VERSION ""

NS_ :

BS_:

BU_: XXX

BO_ 23 BRAKE_RELATED: 8 XXX
 SG_ BRAKE_ON : 0|1@0+ (1,0) [0|1] "" XXX
 SG_ NO_BRAKE : 15|1@0+ (1,0) [0|1] "" XXX

BO_ 24 HYBRID_RELATED: 8 XXX
 SG_ NEW_SIGNAL_1 : 7|13@0+ (1,0) [0|8191] "" XXX
 SG_ NEW_SIGNAL_2 : 38|9@0+ (1,0) [0|511] "" XXX

BO_ 80 ENGINE_START: 8 XXX
 SG_ ENGINE_ON : 1|1@0+ (1,0) [0|1] "" XXX

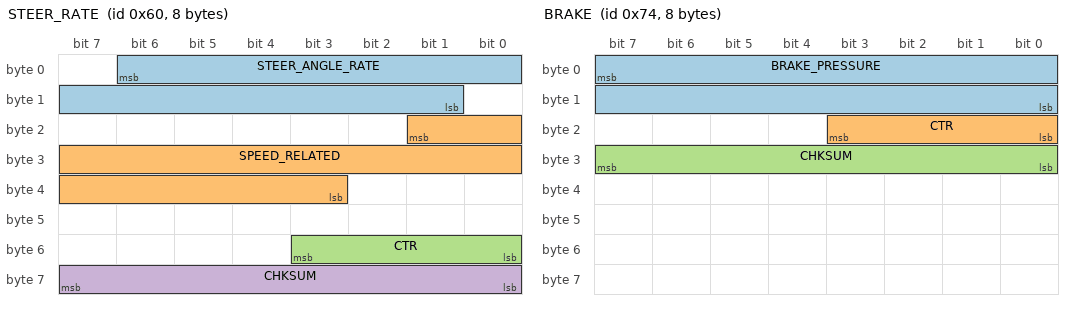
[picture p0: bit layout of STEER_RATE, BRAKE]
BO_ 96 STEER_RATE: 8 XXX
 SG_ STEER_ANGLE_RATE : 6|14@0+ (1,-8192) [0|16383] "" XXX
 SG_ SPEED_RELATED : 17|15@0+ (1,-10000) [0|32767] "" XXX
 SG_ CTR : 51|4@0+ (1,0) [0|15] "" XXX
 SG_ CHKSUM : 63|8@0+ (1,0) [0|255] "" XXX

BO_ 116 BRAKE: 8 XXX
 SG_ BRAKE_PRESSURE : 7|16@0+ (1,0) [0|65535] "" XXX
 SG_ CTR : 19|4@0+ (1,0) [0|15] "" XXX
 SG_ CHKSUM : 31|8@0+ (1,0) [0|255] "" XXX

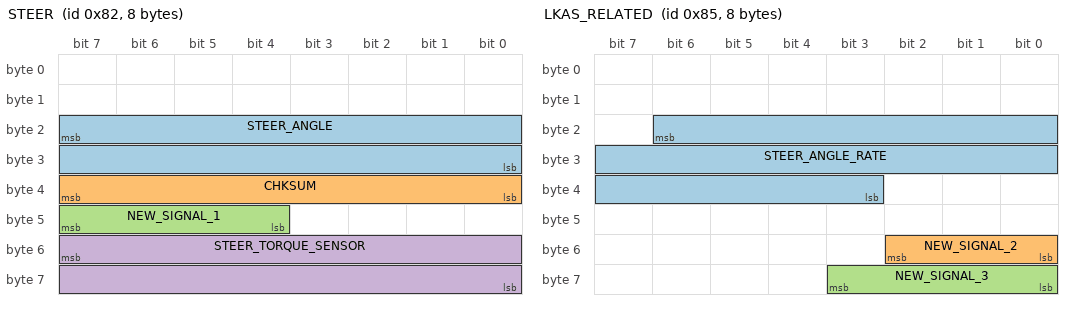
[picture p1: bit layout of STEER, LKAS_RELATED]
BO_ 130 STEER: 8 XXX
 SG_ STEER_ANGLE : 23|16@0+ (0.05,-1600) [500|-500] "deg" XXX
 SG_ CHKSUM : 39|8@0+ (1,0) [0|255] "" XXX
 SG_ NEW_SIGNAL_1 : 47|4@0+ (1,0) [0|15] "" XXX
 SG_ STEER_TORQUE_SENSOR : 55|16@0+ (1,0) [0|65535] "" XXX

BO_ 133 LKAS_RELATED: 8 XXX
 SG_ STEER_ANGLE_RATE : 22|20@0+ (1,0) [0|1048575] "" XXX
 SG_ NEW_SIGNAL_2 : 50|3@0+ (1,0) [0|7] "" XXX
 SG_ NEW_SIGNAL_3 : 59|4@0+ (1,0) [0|15] "" XXX

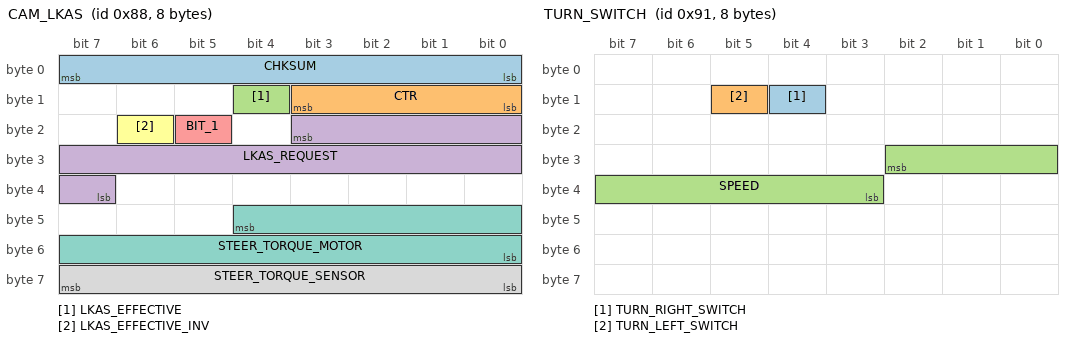
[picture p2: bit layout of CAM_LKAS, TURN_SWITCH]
BO_ 136 CAM_LKAS: 8 XXX
 SG_ CHKSUM : 7|8@0+ (1,0) [0|255] "" XXX
 SG_ CTR : 11|4@0+ (1,0) [0|15] "" XXX
 SG_ LKAS_EFFECTIVE : 12|1@0+ (1,0) [0|1] "" XXX
 SG_ LKAS_REQUEST : 19|13@0+ (1,-4096) [0|8191] "" XXX
 SG_ BIT_1 : 21|1@0+ (1,0) [0|1] "" XXX
 SG_ LKAS_EFFECTIVE_INV : 22|1@0+ (1,0) [0|1] "" XXX
 SG_ STEER_TORQUE_MOTOR : 44|13@0+ (1,-4096) [0|8191] "" XXX
 SG_ STEER_TORQUE_SENSOR : 63|8@0+ (1,-127) [0|255] "" XXX

BO_ 145 TURN_SWITCH: 8 XXX
 SG_ TURN_RIGHT_SWITCH : 12|1@0+ (1,0) [0|3] "" XXX
 SG_ TURN_LEFT_SWITCH : 13|1@0+ (1,0) [0|255] "" XXX
 SG_ SPEED : 26|8@0+ (1,0) [0|255] "" XXX

BO_ 152 BSM_RELATED: 8 XXX
 SG_ FRONT_CT_ALERT : 21|2@0+ (1,0) [0|3] "" XXX

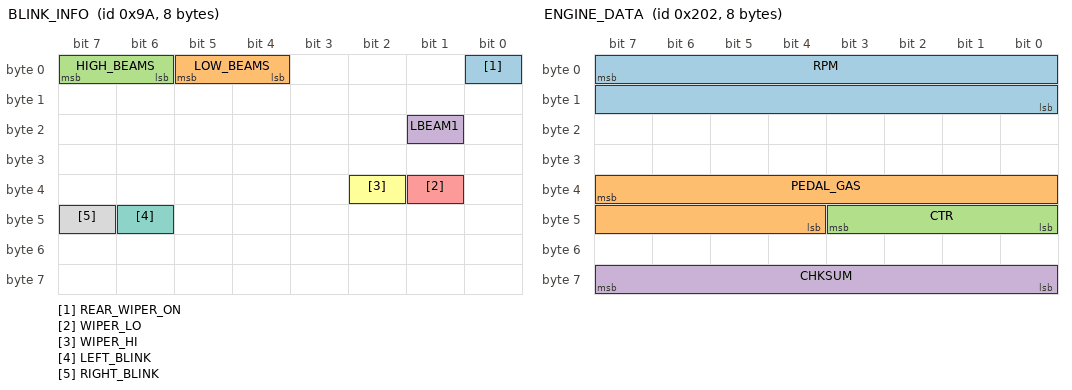
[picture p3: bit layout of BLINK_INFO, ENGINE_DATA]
BO_ 154 BLINK_INFO: 8 XXX
 SG_ REAR_WIPER_ON : 0|1@0+ (1,0) [0|1] "" XXX
 SG_ LOW_BEAMS : 5|2@0+ (1,0) [0|3] "" XXX
 SG_ HIGH_BEAMS : 7|2@0+ (1,0) [0|3] "" XXX
 SG_ LBEAM1 : 17|1@0+ (1,0) [0|1] "" XXX
 SG_ WIPER_LO : 33|1@1+ (1,0) [0|31] "" XXX
 SG_ WIPER_HI : 34|1@0+ (1,0) [0|1] "" XXX
 SG_ LEFT_BLINK : 46|1@0+ (1,0) [0|1] "" XXX
 SG_ RIGHT_BLINK : 47|1@0+ (1,0) [0|1] "" XXX

BO_ 357 PEDALS: 8 XXX
 SG_ BRAKE_ON : 8|1@0+ (1,0) [0|1] "" XXX
 SG_ NO_BRAKE : 23|1@0+ (1,0) [0|1] "" XXX

BO_ 514 ENGINE_DATA: 8 XXX
 SG_ RPM : 7|16@0+ (0.25,0) [0|8500] "rpm" XXX
 SG_ PEDAL_GAS : 39|12@0+ (0.024414,0) [0|4096] "%" XXX
 SG_ CTR : 43|4@0+ (1,0) [0|15] "" XXX
 SG_ CHKSUM : 63|8@0+ (1,0) [0|127] "" XXX

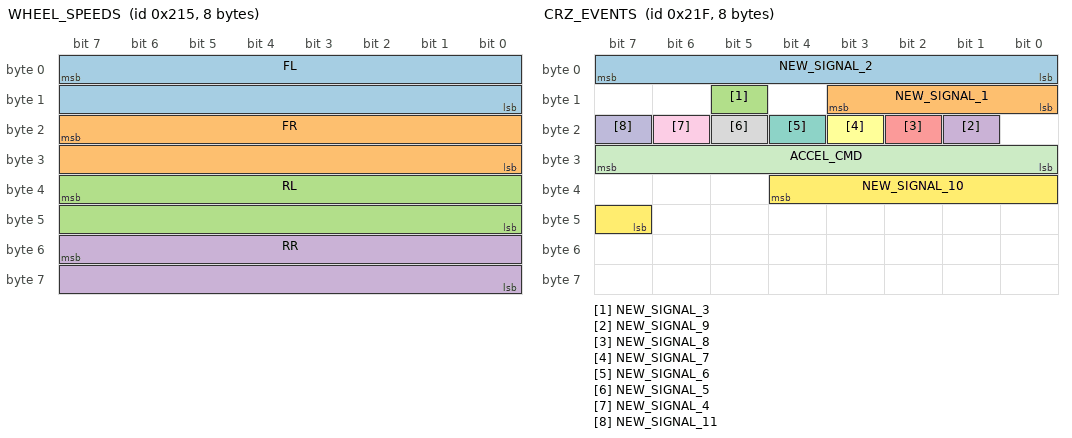
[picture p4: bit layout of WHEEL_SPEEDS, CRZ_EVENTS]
BO_ 533 WHEEL_SPEEDS: 8 XXX
 SG_ FL : 7|16@0+ (0.01,-100) [0|16383] "kph" XXX
 SG_ FR : 23|16@0+ (0.01,-100) [0|65535] "kph" XXX
 SG_ RL : 39|16@0+ (0.01,-100) [0|15] "kph" XXX
 SG_ RR : 55|16@0+ (0.01,-100) [0|65535] "kph" XXX

BO_ 543 CRZ_EVENTS: 8 XXX
 SG_ NEW_SIGNAL_2 : 7|8@0+ (1,0) [0|255] "" XXX
 SG_ NEW_SIGNAL_1 : 11|4@0+ (1,0) [0|15] "" XXX
 SG_ NEW_SIGNAL_3 : 13|1@0+ (1,0) [0|1] "" XXX
 SG_ NEW_SIGNAL_9 : 17|1@0+ (1,0) [0|1] "" XXX
 SG_ NEW_SIGNAL_8 : 18|1@0+ (1,0) [0|1] "" XXX
 SG_ NEW_SIGNAL_7 : 19|1@0+ (1,0) [0|1] "" XXX
 SG_ NEW_SIGNAL_6 : 20|1@0+ (1,0) [0|1] "" XXX
 SG_ NEW_SIGNAL_5 : 21|1@0+ (1,0) [0|1] "" XXX
 SG_ NEW_SIGNAL_4 : 22|1@0+ (1,0) [0|1] "" XXX
 SG_ NEW_SIGNAL_11 : 23|1@0+ (1,0) [0|1] "" XXX
 SG_ ACCEL_CMD : 31|8@0+ (1,0) [0|255] "" XXX
 SG_ NEW_SIGNAL_10 : 36|6@0+ (1,0) [0|63] "" XXX

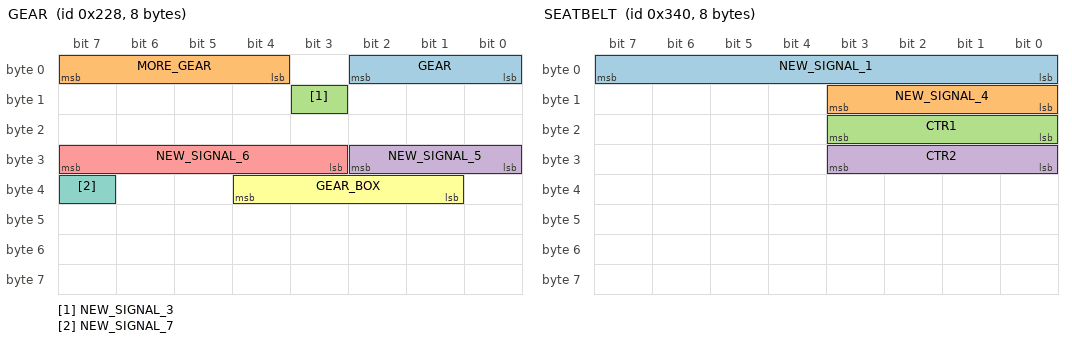
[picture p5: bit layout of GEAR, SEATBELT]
BO_ 552 GEAR: 8 XXX
 SG_ GEAR : 2|3@0+ (1,0) [0|7] "" XXX
 SG_ MORE_GEAR : 7|4@0+ (1,0) [0|15] "" XXX
 SG_ NEW_SIGNAL_3 : 11|1@0+ (1,0) [0|1] "" XXX
 SG_ NEW_SIGNAL_5 : 26|3@0+ (1,0) [0|255] "" XXX
 SG_ NEW_SIGNAL_6 : 31|5@0+ (1,0) [0|31] "" XXX
 SG_ GEAR_BOX : 36|4@0+ (1,0) [0|15] "" XXX
 SG_ NEW_SIGNAL_7 : 39|1@0+ (1,0) [0|255] "" XXX

BO_ 832 SEATBELT: 8 XXX
 SG_ NEW_SIGNAL_1 : 7|8@0+ (1,0) [0|255] "" XXX
 SG_ NEW_SIGNAL_4 : 8|4@1+ (1,0) [0|3] "" XXX
 SG_ CTR1 : 19|4@0+ (1,0) [0|15] "" XXX
 SG_ CTR2 : 27|4@0+ (1,0) [0|15] "" XXX

BO_ 836 VEHICLE_ACC: 8 XXX
 SG_ VEHICLE_ACC_Y : 7|16@0+ (1,-32767) [0|65535] "" XXX
 SG_ VEHICLE_ACC_X : 23|16@0+ (1,-32767) [0|65535] "" XXX

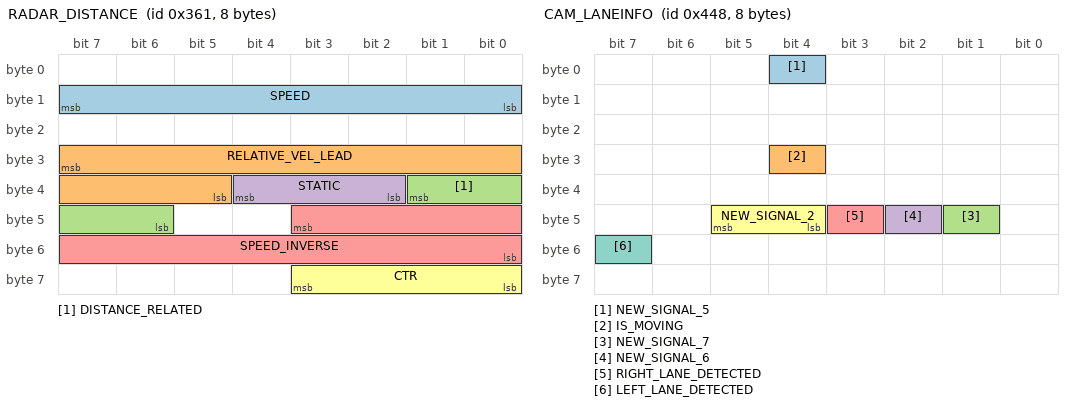
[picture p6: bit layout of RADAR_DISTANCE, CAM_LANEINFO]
BO_ 865 RADAR_DISTANCE: 8 XXX
 SG_ SPEED : 15|8@0+ (1,0) [0|255] "kph" XXX
 SG_ RELATIVE_VEL_LEAD : 31|11@0- (1,0) [0|255] "" XXX
 SG_ DISTANCE_RELATED : 33|4@0+ (1,0) [0|3] "" XXX
 SG_ STATIC : 36|3@0+ (1,0) [0|31] "" XXX
 SG_ SPEED_INVERSE : 43|12@0- (-0.225,0) [0|255] "kph" XXX
 SG_ CTR : 56|4@1+ (1,0) [0|15] "" XXX

BO_ 1096 CAM_LANEINFO: 8 XXX
 SG_ NEW_SIGNAL_5 : 4|1@0+ (1,0) [0|1] "" XXX
 SG_ IS_MOVING : 28|1@0+ (1,0) [0|1] "" XXX
 SG_ NEW_SIGNAL_7 : 41|1@0+ (1,0) [0|1] "" XXX
 SG_ NEW_SIGNAL_6 : 42|1@0+ (1,0) [0|1] "" XXX
 SG_ RIGHT_LANE_DETECTED : 43|1@0+ (1,0) [0|1] "" XXX
 SG_ NEW_SIGNAL_2 : 45|2@0+ (1,0) [0|3] "" XXX
 SG_ LEFT_LANE_DETECTED : 55|1@0+ (1,0) [0|1] "" XXX

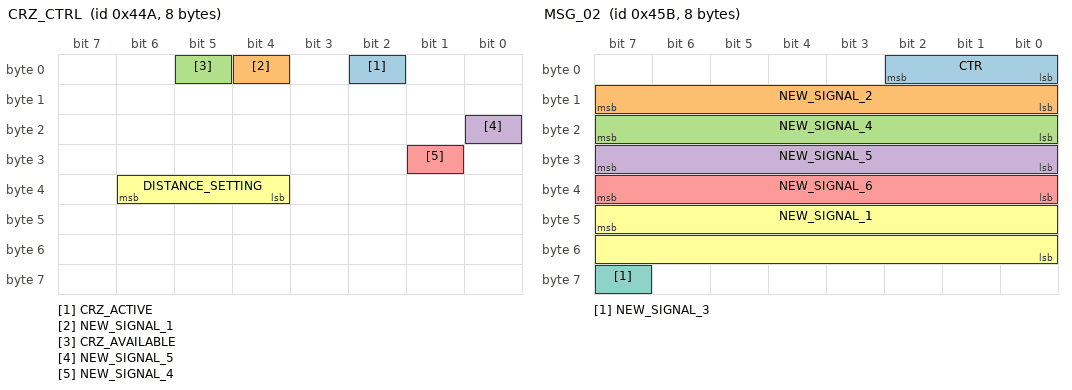
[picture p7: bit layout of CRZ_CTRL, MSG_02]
BO_ 1098 CRZ_CTRL: 8 XXX
 SG_ CRZ_ACTIVE : 2|1@0+ (1,0) [0|1] "" XXX
 SG_ NEW_SIGNAL_1 : 4|1@0+ (1,0) [0|1] "" XXX
 SG_ CRZ_AVAILABLE : 5|1@0+ (1,0) [0|1] "" XXX
 SG_ NEW_SIGNAL_5 : 16|1@0+ (1,0) [0|1] "" XXX
 SG_ NEW_SIGNAL_4 : 25|1@0+ (1,0) [0|1] "" XXX
 SG_ DISTANCE_SETTING : 38|3@0+ (1,0) [0|7] "" XXX

BO_ 1114 NEW_MSG_4: 8 XXX

BO_ 1115 MSG_02: 8 XXX
 SG_ CTR : 2|3@0+ (1,0) [0|255] "" XXX
 SG_ NEW_SIGNAL_2 : 15|8@0+ (1,0) [0|255] "" XXX
 SG_ NEW_SIGNAL_4 : 23|8@0+ (1,0) [0|255] "" XXX
 SG_ NEW_SIGNAL_5 : 31|8@0+ (1,0) [0|255] "" XXX
 SG_ NEW_SIGNAL_6 : 39|8@0+ (1,0) [0|255] "" XXX
 SG_ NEW_SIGNAL_1 : 47|16@0+ (1,0) [0|65535] "" XXX
 SG_ NEW_SIGNAL_3 : 63|1@0+ (1,0) [0|1] "" XXX

CM_ SG_ 145 TURN_RIGHT_SWITCH "CX-50 Hybrid";
CM_ SG_ 145 TURN_LEFT_SWITCH "CX-50 Hybrid";
CM_ SG_ 145 SPEED "CX-50 Hybrid";
CM_ SG_ 552 GEAR "0 Shifting, 1 P, 2 R, 3 N, 4 D";
CM_ SG_ 552 GEAR_BOX "0 P, 14 R, 1 though 6 D for speeds, 15 Shift";
VAL_ 552 GEAR 1 "P" 2 "R" 3 "N" 4 "D";
